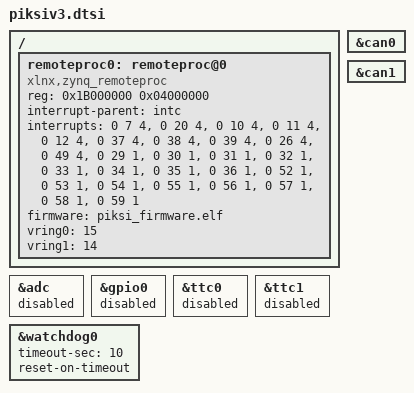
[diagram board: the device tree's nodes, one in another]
/*
 * Copyright (C) 2016 Swift Navigation Inc.
 * Contact: Jacob McNamee <jacob@swiftnav.com>
 *
 * This source is subject to the license found in the file 'LICENSE' which must
 * be be distributed together with this source. All other rights reserved.
 *
 * THIS CODE AND INFORMATION IS PROVIDED "AS IS" WITHOUT WARRANTY OF ANY KIND,
 * EITHER EXPRESSED OR IMPLIED, INCLUDING BUT NOT LIMITED TO THE IMPLIED
 * WARRANTIES OF MERCHANTABILITY AND/OR FITNESS FOR A PARTICULAR PURPOSE.
 */

/include/ "zynq-7000.dtsi"

/ {
  remoteproc0: remoteproc@0 {
    compatible = "xlnx,zynq_remoteproc";
    reg = <0x1B000000 0x04000000>;
    interrupt-parent = <&intc>;
    interrupts =
        <0  7 4>,                                 /* ADC */
        <0 20 4>,                                 /* GPIO */
        <0 10 4>, <0 11 4>, <0 12 4>,             /* TTC0 0-2 */
        <0 37 4>, <0 38 4>, <0 39 4>,             /* TTC1 0-2 */
        <0 26 4>,                                 /* SPI0 */
        <0 49 4>,                                 /* SPI1 */
        <0 29 1>, <0 30 1>, <0 31 1>, <0 32 1>,   /* FPGA 0-3 */
        <0 33 1>, <0 34 1>, <0 35 1>, <0 36 1>,   /* FPGA 4-7 */
        <0 52 1>, <0 53 1>, <0 54 1>, <0 55 1>,   /* FPGA 8-11 */
        <0 56 1>, <0 57 1>, <0 58 1>, <0 59 1>;   /* FPGA 12-15 */
    firmware = "piksi_firmware.elf";
    vring0 = <15>;
    vring1 = <14>;
  };
};

&adc {
  status = "disabled";
};

&gpio0 {
  status = "disabled";
};

&ttc0 {
  status = "disabled";
};

&ttc1 {
  status = "disabled";
};

&watchdog0 {
  timeout-sec = <10>;
  reset-on-timeout;
};

&can0 {
  status = "okay";
};

&can1 {
  status = "okay";
};
